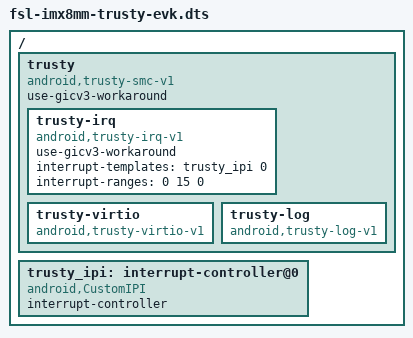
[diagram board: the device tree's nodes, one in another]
/*
 * Copyright 2018 NXP
 *
 * This program is free software; you can redistribute it and/or
 * modify it under the terms of the GNU General Public License
 * as published by the Free Software Foundation; either version 2
 * of the License, or (at your option) any later version.
 *
 * This program is distributed in the hope that it will be useful,
 * but WITHOUT ANY WARRANTY; without even the implied warranty of
 * MERCHANTABILITY or FITNESS FOR A PARTICULAR PURPOSE.  See the
 * GNU General Public License for more details.
 */

/dts-v1/;

#include "fsl-imx8mm-evk.dts"

/ {
	trusty {
		compatible = "android,trusty-smc-v1";
		ranges;
		#address-cells = <2>;
		#size-cells = <2>;
		use-gicv3-workaround;
		trusty-irq {
			use-gicv3-workaround;
			compatible = "android,trusty-irq-v1";
			interrupt-templates = <&trusty_ipi 0>;
			interrupt-ranges = < 0 15 0>;
		};
		trusty-virtio {
			compatible = "android,trusty-virtio-v1";
		};
		trusty-log {
			compatible = "android,trusty-log-v1";
		};
	};
	trusty_ipi: interrupt-controller@0 {
		compatible = "android,CustomIPI";
		interrupt-controller;
		#interrupt-cells = <1>;
	};
};
